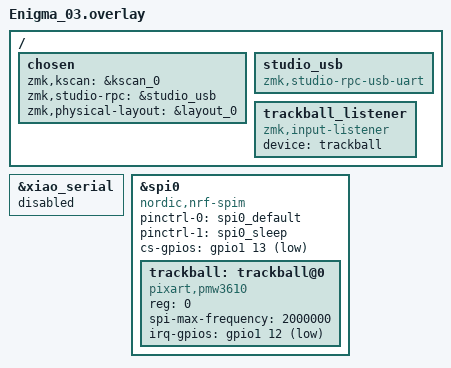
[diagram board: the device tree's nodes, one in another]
#include <input/processors.dtsi>
#include <dt-bindings/zmk/input_transform.h>
#include "Enigma_03.dtsi"

/ {
    chosen {
        zmk,kscan = &kscan_0;
        zmk,studio-rpc = &studio_usb;
        zmk,physical-layout = &layout_0;
    };

    studio_usb: studio_usb {
        compatible = "zmk,studio-rpc-usb-uart";
    };

    trackball_listener {
        compatible = "zmk,input-listener";
        device = <&trackball>;
    };
};

&xiao_serial { 
    status = "disabled"; 
};

&spi0 {
    status = "okay";
    compatible = "nordic,nrf-spim";
    pinctrl-0 = <&spi0_default>;
    pinctrl-1 = <&spi0_sleep>;
    pinctrl-names = "default", "sleep";
    cs-gpios = <&gpio1 13 GPIO_ACTIVE_LOW>; //NCS

    trackball: trackball@0 {
        status = "okay";
        compatible = "pixart,pmw3610";
        reg = <0>;
        spi-max-frequency = <2000000>;
        irq-gpios = <&gpio1 12 (GPIO_ACTIVE_LOW | GPIO_PULL_UP)>; //MOT
    };
};
